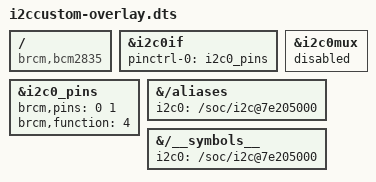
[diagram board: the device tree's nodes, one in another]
/dts-v1/;
/plugin/;

/{
	compatible = "brcm,bcm2835";

    fragment@0 {
        target = <&i2c0if>;
        __overlay__ {
            status = "okay";
            pinctrl-names = "default";
            pinctrl-0 = <&i2c0_pins>;
        };
    };
	fragment@1 {
        target = <&i2c0_pins>;
        pins1: __overlay__ {
            brcm,pins = <0 1>;
            brcm,function = <4>; /* alt0 */
        };
    };
    fragment@6 {
        target = <&i2c0mux>;
        __overlay__ {
            status = "disabled";
        };
    };

    fragment@7 {
        target-path = "/aliases";
        __overlay__ {
            i2c0 = "/soc/i2c@7e205000";
        };
    };

    fragment@8 {
        target-path = "/__symbols__";
        __overlay__ {
            i2c0 = "/soc/i2c@7e205000";
        };
    };
};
